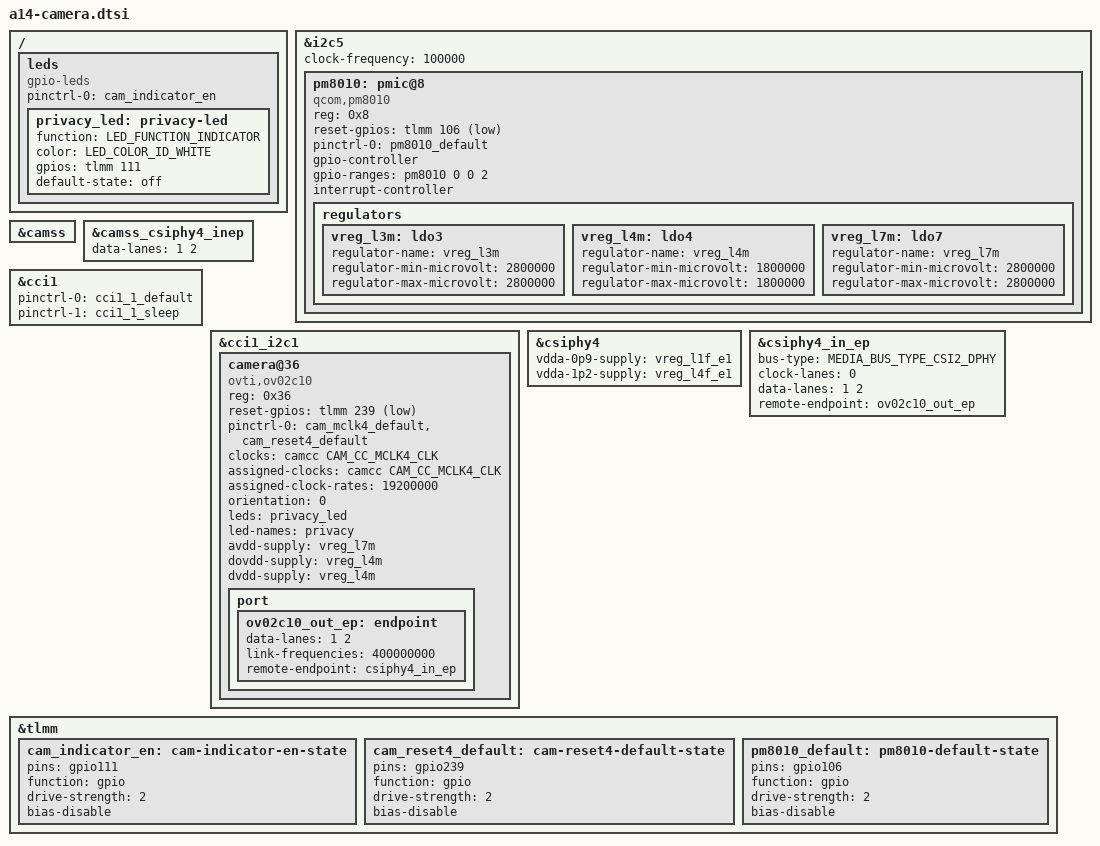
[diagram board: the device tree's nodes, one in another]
/*
 * EXPERIMENTAL: ASUS Zenbook A14 UX3407NA (Glymur) front RGB camera.
 *
 * Appended to the board dts by kernel/a14-camera-post-patch.nix when
 * hardware.asus.zenbookA14.experimental.camera.enable is set.
 *
 * The wiring follows Qualcomm's reference camera layout as used by the Glymur
 * CRD (upstream "Add CCI and CAMSS support for Glymur" DTS series, 2026-09-07)
 * and the Zenbook A16 UX3607OA (linux-msm topic/glymur-laptops). Checked
 * against the A14's own firmware tables (DSDT devices PML0, CAMP, MPCS) and on
 * hardware, 2026-09-10:
 *
 * - Camera PMIC PML0: I2C address 0x08 at 100 kHz on the controller at
 *   0xb94000, which is i2c5. Probed as a PM8010.
 * - Camera platform CAMP: CCI0 and CCI1 register windows, GPIO 99 (shared,
 *   pull-up; MCLK3 pin, purpose unknown) and GPIO 111 (exclusive, no pull),
 *   which is the camera privacy LED as on the A16.
 * - CSIPHY MPCS: CSIPHY0, CSIPHY1 and CSIPHY4, interrupts matching glymur.dtsi.
 * - OV02C10 at 0x36 on CCI1 bus 1 probed and identified itself, so MCLK4,
 *   the reset GPIO 239 and the PM8010 rails below power it correctly.
 *
 * Not described by the firmware tables: the PM8010 reset GPIO (106 on the CRD
 * and A16; the driver only deasserts it) and the exact LDO-to-rail mapping
 * (taken from the A16). The firmware also enables a second sensor device,
 * CAMI, presumably the IR camera for Windows Hello; it is not described here.
 */

#include <dt-bindings/leds/common.h>
#include <dt-bindings/media/video-interfaces.h>

/ {
	leds {
		compatible = "gpio-leds";

		pinctrl-0 = <&cam_indicator_en>;
		pinctrl-names = "default";

		/* Lit by the V4L2 core while the sensor streams. */
		privacy_led: privacy-led {
			function = LED_FUNCTION_INDICATOR;
			color = <LED_COLOR_ID_WHITE>;
			gpios = <&tlmm 111 GPIO_ACTIVE_HIGH>;
			default-state = "off";
		};
	};
};

/* Camera PMIC, firmware device PML0: 0x08 at 100 kHz on i2c5. */
&i2c5 {
	clock-frequency = <100000>;

	status = "okay";

	pm8010: pmic@8 {
		compatible = "qcom,pm8010";
		reg = <0x8>;

		reset-gpios = <&tlmm 106 GPIO_ACTIVE_LOW>;

		pinctrl-0 = <&pm8010_default>;
		pinctrl-names = "default";

		gpio-controller;
		#gpio-cells = <2>;
		gpio-ranges = <&pm8010 0 0 2>;

		interrupt-controller;
		#interrupt-cells = <2>;

		#thermal-sensor-cells = <0>;

		regulators {
			/* L1/L2 and L5/L6 are unused on the A16. */
			vreg_l3m: ldo3 {
				regulator-name = "vreg_l3m";
				regulator-min-microvolt = <2800000>;
				regulator-max-microvolt = <2800000>;
			};

			vreg_l4m: ldo4 {
				regulator-name = "vreg_l4m";
				regulator-min-microvolt = <1800000>;
				regulator-max-microvolt = <1800000>;
			};

			vreg_l7m: ldo7 {
				regulator-name = "vreg_l7m";
				regulator-min-microvolt = <2800000>;
				regulator-max-microvolt = <2800000>;
			};
		};
	};
};

&camss {
	status = "okay";
};

&camss_csiphy4_inep {
	data-lanes = <1 2>;
};

&cci1 {
	pinctrl-0 = <&cci1_1_default>;
	pinctrl-1 = <&cci1_1_sleep>;

	status = "okay";
};

&cci1_i2c1 {
	/* Front RGB sensor, firmware device CAMF. */
	camera@36 {
		compatible = "ovti,ov02c10";
		reg = <0x36>;

		reset-gpios = <&tlmm 239 GPIO_ACTIVE_LOW>;
		pinctrl-0 = <&cam_mclk4_default>, <&cam_reset4_default>;
		pinctrl-names = "default";

		clocks = <&camcc CAM_CC_MCLK4_CLK>;
		assigned-clocks = <&camcc CAM_CC_MCLK4_CLK>;
		assigned-clock-rates = <19200000>;

		orientation = <0>;

		leds = <&privacy_led>;
		led-names = "privacy";

		/* A16 mapping: AVDD from L7 (2.8 V), DOVDD and DVDD from L4 (1.8 V). */
		avdd-supply = <&vreg_l7m>;
		dovdd-supply = <&vreg_l4m>;
		dvdd-supply = <&vreg_l4m>;

		port {
			ov02c10_out_ep: endpoint {
				data-lanes = <1 2>;
				link-frequencies = /bits/ 64 <400000000>;
				remote-endpoint = <&csiphy4_in_ep>;
			};
		};
	};
};

&csiphy4 {
	/* Same F_E1 rails and voltages as the A16 (0.904 V and 1.2 V). */
	vdda-0p9-supply = <&vreg_l1f_e1>;
	vdda-1p2-supply = <&vreg_l4f_e1>;

	status = "okay";
};

&csiphy4_in_ep {
	bus-type = <MEDIA_BUS_TYPE_CSI2_DPHY>;
	clock-lanes = <0>;
	data-lanes = <1 2>;
	remote-endpoint = <&ov02c10_out_ep>;
};

&tlmm {
	cam_indicator_en: cam-indicator-en-state {
		pins = "gpio111";
		function = "gpio";
		drive-strength = <2>;
		bias-disable;
	};

	cam_reset4_default: cam-reset4-default-state {
		pins = "gpio239";
		function = "gpio";
		drive-strength = <2>;
		bias-disable;
	};

	pm8010_default: pm8010-default-state {
		pins = "gpio106";
		function = "gpio";
		drive-strength = <2>;
		bias-disable;
	};
};
